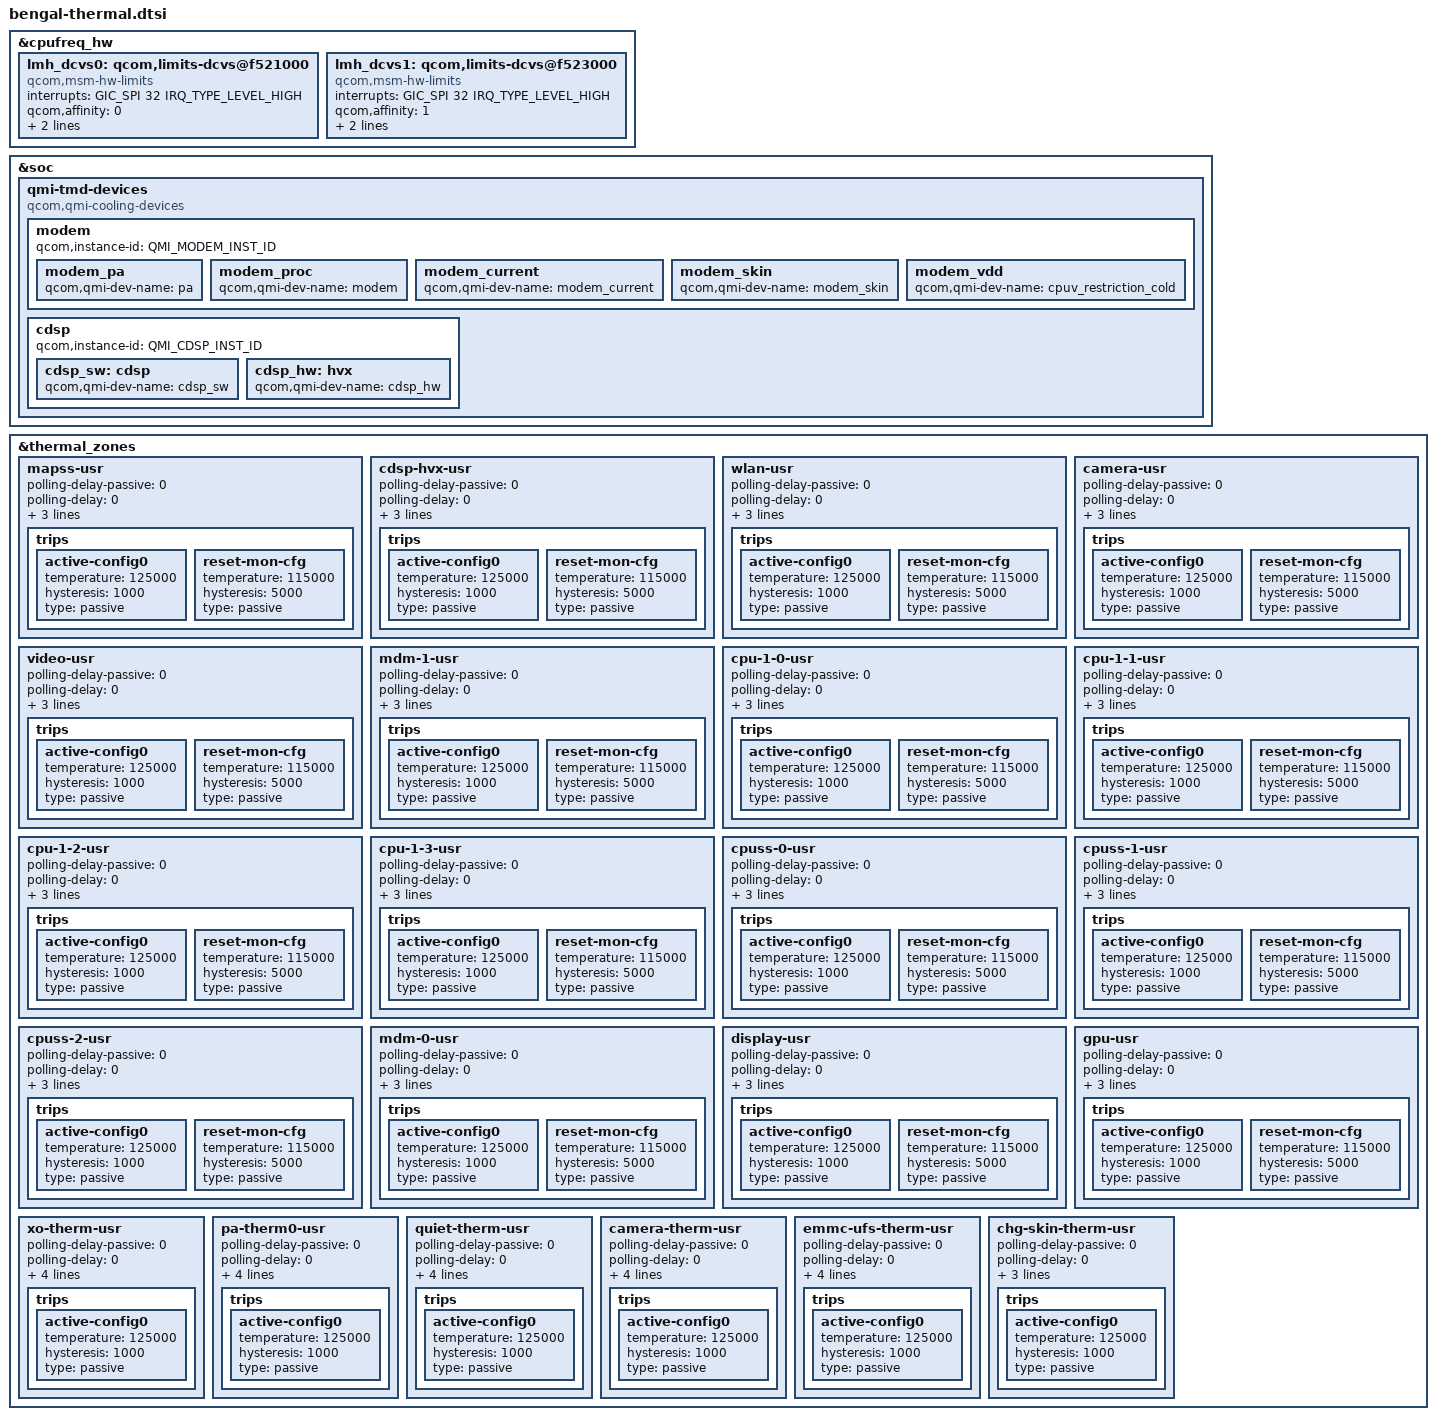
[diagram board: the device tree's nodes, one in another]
#include <dt-bindings/thermal/thermal.h>
#include <dt-bindings/thermal/qmi_thermal.h>

&cpufreq_hw {
	#address-cells = <1>;
	#size-cells = <1>;
	lmh_dcvs0: qcom,limits-dcvs@f521000 {
		compatible = "qcom,msm-hw-limits";
		interrupts = <GIC_SPI 32 IRQ_TYPE_LEVEL_HIGH>;
		qcom,affinity = <0>;
		reg = <0xf550800 0x1000>,
			<0xf521000 0x1000>;
		qcom,no-cooling-device-register;
		#thermal-sensor-cells = <0>;
	};

	lmh_dcvs1: qcom,limits-dcvs@f523000 {
		compatible = "qcom,msm-hw-limits";
		interrupts = <GIC_SPI 32 IRQ_TYPE_LEVEL_HIGH>;
		qcom,affinity = <1>;
		reg = <0xf550800 0x1000>,
			<0xf523000 0x1000>;
		qcom,no-cooling-device-register;
		#thermal-sensor-cells = <0>;
	};
};

&soc {
	qmi-tmd-devices {
		compatible = "qcom,qmi-cooling-devices";

		modem {
			qcom,instance-id = <QMI_MODEM_INST_ID>;

			modem_pa: modem_pa {
				qcom,qmi-dev-name = "pa";
				#cooling-cells = <2>;
			};

			modem_proc: modem_proc {
				qcom,qmi-dev-name = "modem";
				#cooling-cells = <2>;
			};

			modem_current: modem_current {
				qcom,qmi-dev-name = "modem_current";
				#cooling-cells = <2>;
			};

			modem_skin: modem_skin {
				qcom,qmi-dev-name = "modem_skin";
				#cooling-cells = <2>;
			};

			modem_vdd: modem_vdd {
				qcom,qmi-dev-name = "cpuv_restriction_cold";
				#cooling-cells = <2>;
			};
		};

		cdsp {
			qcom,instance-id = <QMI_CDSP_INST_ID>;

			cdsp_sw: cdsp {
				qcom,qmi-dev-name = "cdsp_sw";
				#cooling-cells = <2>;
			};

			cdsp_hw: hvx {
				qcom,qmi-dev-name = "cdsp_hw";
				#cooling-cells = <2>;
			};
		};
	};
};

&thermal_zones {
	mapss-usr {
		polling-delay-passive = <0>;
		polling-delay = <0>;
		thermal-governor = "user_space";
		thermal-sensors = <&tsens0 0>;
		wake-capable-sensor;
		trips {
			active-config0 {
				temperature = <125000>;
				hysteresis = <1000>;
				type = "passive";
			};

			reset-mon-cfg {
				temperature = <115000>;
				hysteresis = <5000>;
				type = "passive";
			};
		};
	};

	cdsp-hvx-usr {
		polling-delay-passive = <0>;
		polling-delay = <0>;
		thermal-governor = "user_space";
		thermal-sensors = <&tsens0 1>;
		wake-capable-sensor;
		trips {
			active-config0 {
				temperature = <125000>;
				hysteresis = <1000>;
				type = "passive";
			};

			reset-mon-cfg {
				temperature = <115000>;
				hysteresis = <5000>;
				type = "passive";
			};
		};
	};

	wlan-usr {
		polling-delay-passive = <0>;
		polling-delay = <0>;
		thermal-governor = "user_space";
		thermal-sensors = <&tsens0 2>;
		wake-capable-sensor;
		trips {
			active-config0 {
				temperature = <125000>;
				hysteresis = <1000>;
				type = "passive";
			};

			reset-mon-cfg {
				temperature = <115000>;
				hysteresis = <5000>;
				type = "passive";
			};
		};
	};

	camera-usr {
		polling-delay-passive = <0>;
		polling-delay = <0>;
		thermal-governor = "user_space";
		thermal-sensors = <&tsens0 3>;
		wake-capable-sensor;
		trips {
			active-config0 {
				temperature = <125000>;
				hysteresis = <1000>;
				type = "passive";
			};

			reset-mon-cfg {
				temperature = <115000>;
				hysteresis = <5000>;
				type = "passive";
			};
		};
	};

	video-usr {
		polling-delay-passive = <0>;
		polling-delay = <0>;
		thermal-governor = "user_space";
		thermal-sensors = <&tsens0 4>;
		wake-capable-sensor;
		trips {
			active-config0 {
				temperature = <125000>;
				hysteresis = <1000>;
				type = "passive";
			};

			reset-mon-cfg {
				temperature = <115000>;
				hysteresis = <5000>;
				type = "passive";
			};
		};
	};

	mdm-1-usr {
		polling-delay-passive = <0>;
		polling-delay = <0>;
		thermal-governor = "user_space";
		thermal-sensors = <&tsens0 5>;
		wake-capable-sensor;
		trips {
			active-config0 {
				temperature = <125000>;
				hysteresis = <1000>;
				type = "passive";
			};

			reset-mon-cfg {
				temperature = <115000>;
				hysteresis = <5000>;
				type = "passive";
			};
		};
	};

	cpu-1-0-usr {
		polling-delay-passive = <0>;
		polling-delay = <0>;
		thermal-governor = "user_space";
		thermal-sensors = <&tsens0 6>;
		wake-capable-sensor;
		trips {
			active-config0 {
				temperature = <125000>;
				hysteresis = <1000>;
				type = "passive";
			};

			reset-mon-cfg {
				temperature = <115000>;
				hysteresis = <5000>;
				type = "passive";
			};
		};
	};

	cpu-1-1-usr {
		polling-delay-passive = <0>;
		polling-delay = <0>;
		thermal-governor = "user_space";
		thermal-sensors = <&tsens0 7>;
		wake-capable-sensor;
		trips {
			active-config0 {
				temperature = <125000>;
				hysteresis = <1000>;
				type = "passive";
			};

			reset-mon-cfg {
				temperature = <115000>;
				hysteresis = <5000>;
				type = "passive";
			};
		};
	};

	cpu-1-2-usr {
		polling-delay-passive = <0>;
		polling-delay = <0>;
		thermal-governor = "user_space";
		thermal-sensors = <&tsens0 8>;
		wake-capable-sensor;
		trips {
			active-config0 {
				temperature = <125000>;
				hysteresis = <1000>;
				type = "passive";
			};

			reset-mon-cfg {
				temperature = <115000>;
				hysteresis = <5000>;
				type = "passive";
			};
		};
	};

	cpu-1-3-usr {
		polling-delay-passive = <0>;
		polling-delay = <0>;
		thermal-governor = "user_space";
		thermal-sensors = <&tsens0 9>;
		wake-capable-sensor;
		trips {
			active-config0 {
				temperature = <125000>;
				hysteresis = <1000>;
				type = "passive";
			};

			reset-mon-cfg {
				temperature = <115000>;
				hysteresis = <5000>;
				type = "passive";
			};
		};
	};

	cpuss-0-usr {
		polling-delay-passive = <0>;
		polling-delay = <0>;
		thermal-governor = "user_space";
		thermal-sensors = <&tsens0 10>;
		wake-capable-sensor;
		trips {
			active-config0 {
				temperature = <125000>;
				hysteresis = <1000>;
				type = "passive";
			};

			reset-mon-cfg {
				temperature = <115000>;
				hysteresis = <5000>;
				type = "passive";
			};
		};
	};

	cpuss-1-usr {
		polling-delay-passive = <0>;
		polling-delay = <0>;
		thermal-governor = "user_space";
		thermal-sensors = <&tsens0 11>;
		wake-capable-sensor;
		trips {
			active-config0 {
				temperature = <125000>;
				hysteresis = <1000>;
				type = "passive";
			};

			reset-mon-cfg {
				temperature = <115000>;
				hysteresis = <5000>;
				type = "passive";
			};
		};
	};

	cpuss-2-usr {
		polling-delay-passive = <0>;
		polling-delay = <0>;
		thermal-governor = "user_space";
		thermal-sensors = <&tsens0 12>;
		wake-capable-sensor;
		trips {
			active-config0 {
				temperature = <125000>;
				hysteresis = <1000>;
				type = "passive";
			};

			reset-mon-cfg {
				temperature = <115000>;
				hysteresis = <5000>;
				type = "passive";
			};
		};
	};

	mdm-0-usr {
		polling-delay-passive = <0>;
		polling-delay = <0>;
		thermal-governor = "user_space";
		thermal-sensors = <&tsens0 13>;
		wake-capable-sensor;
		trips {
			active-config0 {
				temperature = <125000>;
				hysteresis = <1000>;
				type = "passive";
			};

			reset-mon-cfg {
				temperature = <115000>;
				hysteresis = <5000>;
				type = "passive";
			};
		};
	};

	display-usr {
		polling-delay-passive = <0>;
		polling-delay = <0>;
		thermal-governor = "user_space";
		thermal-sensors = <&tsens0 14>;
		wake-capable-sensor;
		trips {
			active-config0 {
				temperature = <125000>;
				hysteresis = <1000>;
				type = "passive";
			};

			reset-mon-cfg {
				temperature = <115000>;
				hysteresis = <5000>;
				type = "passive";
			};
		};
	};

	gpu-usr {
		polling-delay-passive = <0>;
		polling-delay = <0>;
		thermal-governor = "user_space";
		thermal-sensors = <&tsens0 15>;
		wake-capable-sensor;
		trips {
			active-config0 {
				temperature = <125000>;
				hysteresis = <1000>;
				type = "passive";
			};

			reset-mon-cfg {
				temperature = <115000>;
				hysteresis = <5000>;
				type = "passive";
			};
		};
	};

	xo-therm-usr {
		polling-delay-passive = <0>;
		polling-delay = <0>;
		thermal-governor = "user_space";
		thermal-sensors = <&pm6125_adc_tm ADC_XO_THERM_PU2>;
		wake-capable-sensor;
		trips {
			active-config0 {
				temperature = <125000>;
				hysteresis = <1000>;
				type = "passive";
			};
		};
	};

	pa-therm0-usr {
		polling-delay-passive = <0>;
		polling-delay = <0>;
		thermal-governor = "user_space";
		thermal-sensors = <&pm6125_adc_tm ADC_AMUX_THM1_PU2>;
		wake-capable-sensor;
		trips {
			active-config0 {
				temperature = <125000>;
				hysteresis = <1000>;
				type = "passive";
			};
		};
	};

	quiet-therm-usr {
		polling-delay-passive = <0>;
		polling-delay = <0>;
		thermal-governor = "user_space";
		thermal-sensors = <&pm6125_adc_tm ADC_AMUX_THM2_PU2>;
		wake-capable-sensor;
		trips {
			active-config0 {
				temperature = <125000>;
				hysteresis = <1000>;
				type = "passive";
			};
		};
	};

	camera-therm-usr {
		polling-delay-passive = <0>;
		polling-delay = <0>;
		thermal-governor = "user_space";
		thermal-sensors = <&pm6125_adc_tm_iio ADC_GPIO1_PU2>;
		wake-capable-sensor;
		trips {
			active-config0 {
				temperature = <125000>;
				hysteresis = <1000>;
				type = "passive";
			};
		};
	};

	emmc-ufs-therm-usr {
		polling-delay-passive = <0>;
		polling-delay = <0>;
		thermal-governor = "user_space";
		thermal-sensors = <&pm6125_adc_tm_iio ADC_GPIO2_PU2>;
		wake-capable-sensor;
		trips {
			active-config0 {
				temperature = <125000>;
				hysteresis = <1000>;
				type = "passive";
			};
		};
	};

	chg-skin-therm-usr {
		polling-delay-passive = <0>;
		polling-delay = <0>;
		thermal-governor = "user_space";
		thermal-sensors = <&pmi632_adc_tm ADC_GPIO2_PU2>;
		wake-capable-sensor;
		trips {
			active-config0 {
				temperature = <125000>;
				hysteresis = <1000>;
				type = "passive";
			};
		};
	};
};
